AUTOSAR XML (schema 00044)
package /COM/VECTOR/CFG/WORKFLOW/SYSDESC/SYNC
  system SYSTEM: category=ECU_EXTRACT
    system mapping MAPPINGS
      data-mappings:
        data-element=COMPOSITIONTYPE.VehSpd.VehSpd, system-signal=VehSpd
        data-element=COMPOSITIONTYPE.Hr.Hr, system-signal=Hr
        data-element=COMPOSITIONTYPE.Mth.Mth, system-signal=Mth
        data-element=COMPOSITIONTYPE.ComfEna.ComfEna, system-signal=ComfEna
        data-element=COMPOSITIONTYPE.VehState.VehState, system-signal=VehState
        data-element=COMPOSITIONTYPE.Yr.Yr, system-signal=Yr
        data-element=COMPOSITIONTYPE.CGW_03_CRC.CGW_03_CRC, system-signal=CGW_03_CRC
        data-element=COMPOSITIONTYPE.WLCChrgFctEnaReq.WLCChrgFctEnaReq, system-signal=WLCChrgFctEnaReq
        data-element=COMPOSITIONTYPE.Day.Day, system-signal=Day
        data-element=COMPOSITIONTYPE.CGW_03_MsgCntr.CGW_03_MsgCntr, system-signal=CGW_03_MsgCntr
        data-element=COMPOSITIONTYPE.Sec.Sec, system-signal=Sec
        data-element=COMPOSITIONTYPE.VehOdometer.VehOdometer, system-signal=VehOdometer
        data-element=COMPOSITIONTYPE.Min.Min, system-signal=Min
        data-element=COMPOSITIONTYPE.VehState_ASIL.VehState_ASIL, system-signal=VehState_ASIL
        data-element=COMPOSITIONTYPE.ComfEna_ASIL.ComfEna_ASIL, system-signal=ComfEna_ASIL
        data-element=COMPOSITIONTYPE.ImobEnaReq.ImobEnaReq, system-signal=ImobEnaReq
        data-element=COMPOSITIONTYPE.CGW_WLC_MsgCntr.CGW_WLC_MsgCntr, system-signal=CGW_WLC_MsgCntr
        data-element=COMPOSITIONTYPE.CGW_WLC_CRC.CGW_WLC_CRC, system-signal=CGW_WLC_CRC
        data-element=COMPOSITIONTYPE.WLCImobSts.WLCImobSts, system-signal=WLCImobSts
        data-element=COMPOSITIONTYPE.UsrData0_WLC.UsrData0_WLC, system-signal=UsrData0_WLC
        data-element=COMPOSITIONTYPE.WLC_01_MsgCntr.WLC_01_MsgCntr, system-signal=WLC_01_MsgCntr
        data-element=COMPOSITIONTYPE.WLCChrgSts.WLCChrgSts, system-signal=WLCChrgSts
        data-element=COMPOSITIONTYPE.WLCCtrlSts.WLCCtrlSts, system-signal=WLCCtrlSts
        data-element=COMPOSITIONTYPE.WLC_02_MsgCntr.WLC_02_MsgCntr, system-signal=WLC_02_MsgCntr
        data-element=COMPOSITIONTYPE.UsrData4_WLC.UsrData4_WLC, system-signal=UsrData4_WLC
        data-element=COMPOSITIONTYPE.UsrData3_WLC.UsrData3_WLC, system-signal=UsrData3_WLC
        data-element=COMPOSITIONTYPE.UsrData1_WLC.UsrData1_WLC, system-signal=UsrData1_WLC
        data-element=COMPOSITIONTYPE.WLCFailSts.WLCFailSts, system-signal=WLCFailSts
        data-element=COMPOSITIONTYPE.WLC_01_CRC.WLC_01_CRC, system-signal=WLC_01_CRC
        data-element=COMPOSITIONTYPE.WLCMuteViaHW.WLCMuteViaHW, system-signal=WLCMuteViaHW
        data-element=COMPOSITIONTYPE.UsrData2_WLC.UsrData2_WLC, system-signal=UsrData2_WLC
        data-element=COMPOSITIONTYPE.UsrData5_WLC.UsrData5_WLC, system-signal=UsrData5_WLC
        data-element=COMPOSITIONTYPE.WLCChrgRate.WLCChrgRate, system-signal=WLCChrgRate
    root-software-compositions:
      root sw composition prototype COMPOSITIONTYPE: flat-map=FLATMAP, software-composition=COMPOSITIONTYPE
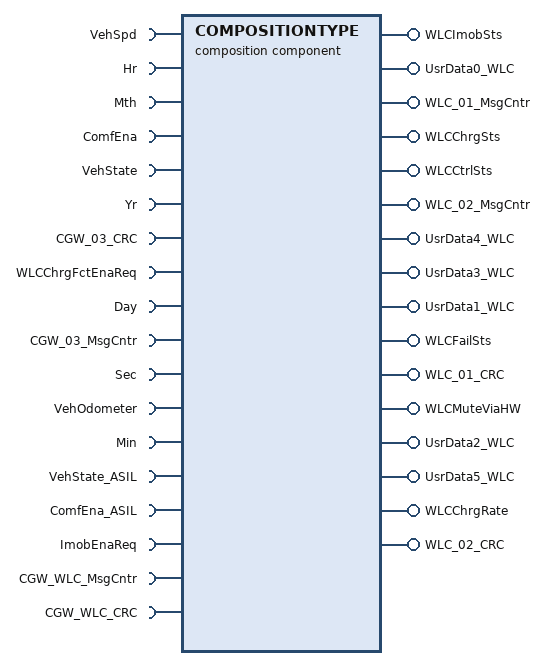
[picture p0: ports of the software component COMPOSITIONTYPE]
  composition sw component type COMPOSITIONTYPE  # UB:Derived from original system description
    18 x require port:
      VehSpd: nonqueued-receiver-com-spec{data-element=VehSpd, init-value=0}, required-interface=VehSpd
      Hr: nonqueued-receiver-com-spec{data-element=Hr, init-value=0}, required-interface=Hr
      Mth: nonqueued-receiver-com-spec{data-element=Mth, init-value=0}, required-interface=Mth
      ComfEna: nonqueued-receiver-com-spec{data-element=ComfEna, init-value=0}, required-interface=ComfEna
      VehState: nonqueued-receiver-com-spec{data-element=VehState, init-value=0}, required-interface=VehState
      Yr: nonqueued-receiver-com-spec{data-element=Yr, init-value=0}, required-interface=Yr
      CGW_03_CRC: nonqueued-receiver-com-spec{data-element=CGW_03_CRC, init-value=0}, required-interface=CGW_03_CRC
      WLCChrgFctEnaReq: nonqueued-receiver-com-spec{data-element=WLCChrgFctEnaReq, init-value=0}, required-interface=WLCChrgFctEnaReq
      Day: nonqueued-receiver-com-spec{data-element=Day, init-value=0}, required-interface=Day
      CGW_03_MsgCntr: nonqueued-receiver-com-spec{data-element=CGW_03_MsgCntr, init-value=0}, required-interface=CGW_03_MsgCntr
      Sec: nonqueued-receiver-com-spec{data-element=Sec, init-value=0}, required-interface=Sec
      VehOdometer: nonqueued-receiver-com-spec{data-element=VehOdometer, init-value=0}, required-interface=VehOdometer
      Min: nonqueued-receiver-com-spec{data-element=Min, init-value=0}, required-interface=Min
      VehState_ASIL: nonqueued-receiver-com-spec{data-element=VehState_ASIL, init-value=0}, required-interface=VehState_ASIL
      ComfEna_ASIL: nonqueued-receiver-com-spec{data-element=ComfEna_ASIL, init-value=0}, required-interface=ComfEna_ASIL
      ImobEnaReq: nonqueued-receiver-com-spec{data-element=ImobEnaReq, init-value=0}, required-interface=ImobEnaReq
      CGW_WLC_MsgCntr: nonqueued-receiver-com-spec{data-element=CGW_WLC_MsgCntr, init-value=0}, required-interface=CGW_WLC_MsgCntr
      CGW_WLC_CRC: nonqueued-receiver-com-spec{data-element=CGW_WLC_CRC, init-value=0}, required-interface=CGW_WLC_CRC
    16 x provide port:
      WLCImobSts: nonqueued-sender-com-spec{data-element=WLCImobSts, init-value=0}, provided-interface=WLCImobSts
      UsrData0_WLC: nonqueued-sender-com-spec{data-element=UsrData0_WLC, init-value=0}, provided-interface=UsrData0_WLC
      WLC_01_MsgCntr: nonqueued-sender-com-spec{data-element=WLC_01_MsgCntr, init-value=0}, provided-interface=WLC_01_MsgCntr
      WLCChrgSts: nonqueued-sender-com-spec{data-element=WLCChrgSts, init-value=0}, provided-interface=WLCChrgSts
      WLCCtrlSts: nonqueued-sender-com-spec{data-element=WLCCtrlSts, init-value=0}, provided-interface=WLCCtrlSts
      WLC_02_MsgCntr: nonqueued-sender-com-spec{data-element=WLC_02_MsgCntr, init-value=0}, provided-interface=WLC_02_MsgCntr
      UsrData4_WLC: nonqueued-sender-com-spec{data-element=UsrData4_WLC, init-value=0}, provided-interface=UsrData4_WLC
      UsrData3_WLC: nonqueued-sender-com-spec{data-element=UsrData3_WLC, init-value=0}, provided-interface=UsrData3_WLC
      UsrData1_WLC: nonqueued-sender-com-spec{data-element=UsrData1_WLC, init-value=0}, provided-interface=UsrData1_WLC
      WLCFailSts: nonqueued-sender-com-spec{data-element=WLCFailSts, init-value=0}, provided-interface=WLCFailSts
      WLC_01_CRC: nonqueued-sender-com-spec{data-element=WLC_01_CRC, init-value=0}, provided-interface=WLC_01_CRC
      WLCMuteViaHW: nonqueued-sender-com-spec{data-element=WLCMuteViaHW, init-value=0}, provided-interface=WLCMuteViaHW
      UsrData2_WLC: nonqueued-sender-com-spec{data-element=UsrData2_WLC, init-value=0}, provided-interface=UsrData2_WLC
      UsrData5_WLC: nonqueued-sender-com-spec{data-element=UsrData5_WLC, init-value=0}, provided-interface=UsrData5_WLC
      WLCChrgRate: nonqueued-sender-com-spec{data-element=WLCChrgRate, init-value=0}, provided-interface=WLCChrgRate
      WLC_02_CRC: nonqueued-sender-com-spec=WLC_02_CRC, provided-interface=WLC_02_CRC
    10 x component:
      ComM: type=ComM
      DemMaster_0: type=DemMaster_0
      DemSatellite_0: type=DemSatellite_0
      Det: type=Det
      EcuM: type=EcuM
      Os_OsCore0_swc: type=Os_OsCore0_swc
      BswM: type=BswM
      Dcm: type=Dcm
      SWC_WLCAPP: type=SWC_WLCAPP
      Communication_Read_APP: type=Communication_Read_APP
    connect BswM.Switch_ESH_ModeSwitch -> BswM.Notification_ESH_ModeNotification
    connect ComM.UR_CN_NIO_ES6_RF_CAN_SR_V3_0_e01a4c57 -> SWC_WLCAPP.UR_CN_NIO_ES6_RF_CAN_SR_V3_0_e01a4c57
    delegate Communication_Read_APP.Yr <-> outer port Yr  # UB:Derived from original system description
    delegate Communication_Read_APP.Hr <-> outer port Hr  # UB:Derived from original system description
    delegate Communication_Read_APP.Min <-> outer port Min  # UB:Derived from original system description
    delegate Communication_Read_APP.WLCChrgFctEnaReq <-> outer port WLCChrgFctEnaReq  # UB:Derived from original system description
    delegate Communication_Read_APP.ImobEnaReq <-> outer port ImobEnaReq  # UB:Derived from original system description
    delegate Communication_Read_APP.CGW_WLC_MsgCntr <-> outer port CGW_WLC_MsgCntr  # UB:Derived from original system description
    delegate Communication_Read_APP.VehOdometer <-> outer port VehOdometer  # UB:Derived from original system description
    delegate Communication_Read_APP.CGW_WLC_CRC <-> outer port CGW_WLC_CRC  # UB:Derived from original system description
    delegate Communication_Read_APP.CGW_03_MsgCntr <-> outer port CGW_03_MsgCntr  # UB:Derived from original system description
    delegate Communication_Read_APP.ComfEna_ASIL <-> outer port ComfEna_ASIL  # UB:Derived from original system description
    delegate Communication_Read_APP.VehState_ASIL <-> outer port VehState_ASIL  # UB:Derived from original system description
    delegate Communication_Read_APP.VehState <-> outer port VehState  # UB:Derived from original system description
    delegate Communication_Read_APP.CGW_03_CRC <-> outer port CGW_03_CRC  # UB:Derived from original system description
    delegate Communication_Read_APP.ComfEna <-> outer port ComfEna  # UB:Derived from original system description
    delegate Communication_Read_APP.Day <-> outer port Day  # UB:Derived from original system description
    delegate Communication_Read_APP.Mth <-> outer port Mth  # UB:Derived from original system description
    delegate Communication_Read_APP.Sec <-> outer port Sec  # UB:Derived from original system description
    delegate Communication_Read_APP.VehSpd <-> outer port VehSpd  # UB:Derived from original system description
    delegate Communication_Read_APP.WLC_02_CRC <-> outer port WLC_02_CRC  # UB:Derived from original system description
    delegate Communication_Read_APP.UsrData5_WLC <-> outer port UsrData5_WLC  # UB:Derived from original system description
    delegate Communication_Read_APP.WLCCtrlSts <-> outer port WLCCtrlSts  # UB:Derived from original system description
    delegate Communication_Read_APP.UsrData4_WLC <-> outer port UsrData4_WLC  # UB:Derived from original system description
    delegate Communication_Read_APP.UsrData0_WLC <-> outer port UsrData0_WLC  # UB:Derived from original system description
    delegate Communication_Read_APP.WLCFailSts <-> outer port WLCFailSts  # UB:Derived from original system description
    delegate Communication_Read_APP.UsrData3_WLC <-> outer port UsrData3_WLC  # UB:Derived from original system description
    delegate Communication_Read_APP.WLCMuteViaHW <-> outer port WLCMuteViaHW  # UB:Derived from original system description
    delegate Communication_Read_APP.WLC_01_CRC <-> outer port WLC_01_CRC  # UB:Derived from original system description
    delegate Communication_Read_APP.WLCImobSts <-> outer port WLCImobSts  # UB:Derived from original system description
    delegate Communication_Read_APP.WLC_02_MsgCntr <-> outer port WLC_02_MsgCntr  # UB:Derived from original system description
    delegate Communication_Read_APP.UsrData2_WLC <-> outer port UsrData2_WLC  # UB:Derived from original system description
    delegate Communication_Read_APP.WLCChrgRate <-> outer port WLCChrgRate  # UB:Derived from original system description
    delegate Communication_Read_APP.WLCChrgSts <-> outer port WLCChrgSts  # UB:Derived from original system description
    delegate Communication_Read_APP.UsrData1_WLC <-> outer port UsrData1_WLC  # UB:Derived from original system description
    delegate Communication_Read_APP.WLC_01_MsgCntr <-> outer port WLC_01_MsgCntr  # UB:Derived from original system description
    connect Dcm.DcmEcuReset -> Communication_Read_APP.DcmEcuReset
    connect Communication_Read_APP.DataServices_Diag_RWDI_LightOnOffCounter_LightOnOffCounter_Value -> Dcm.DataServices_Diag_RWDI_LightOnOffCounter_LightOnOffCounter_Value
    connect Communication_Read_APP.DataServices_Diag_VM_HardwarePartNumber -> Dcm.DataServices_Diag_VM_HardwarePartNumber
    connect Communication_Read_APP.DataServices_DcmDspData_BootloaderVersion -> Dcm.DataServices_DcmDspData_BootloaderVersion
    connect Communication_Read_APP.DataServices_DcmDspData_ConfigurarionFingerprint -> Dcm.DataServices_DcmDspData_ConfigurarionFingerprint
    connect Communication_Read_APP.DataServices_DcmDspData_ECUConfigurarion -> Dcm.DataServices_DcmDspData_ECUConfigurarion
    connect Communication_Read_APP.DataServices_DcmDspData_ECUDiagDatabaseVersion -> Dcm.DataServices_DcmDspData_ECUDiagDatabaseVersion
    connect Communication_Read_APP.DataServices_DcmDspData_ECUManufacturingDate -> Dcm.DataServices_DcmDspData_ECUManufacturingDate
    connect Communication_Read_APP.DataServices_DcmDspData_ECUProgrammingDate -> Dcm.DataServices_DcmDspData_ECUProgrammingDate
    connect Communication_Read_APP.DataServices_DcmDspData_ECUSerialNumber -> Dcm.DataServices_DcmDspData_ECUSerialNumber
    connect Communication_Read_APP.DataServices_DcmDspData_ReadActiveDiagSession -> Dcm.DataServices_DcmDspData_ReadActiveDiagSession
    connect Communication_Read_APP.DataServices_DcmDspData_ReadFingerprint -> Dcm.DataServices_DcmDspData_ReadFingerprint
    connect Communication_Read_APP.DataServices_DcmDspData_RepairShopFingerPrint -> Dcm.DataServices_DcmDspData_RepairShopFingerPrint
    connect Communication_Read_APP.DataServices_DcmDspData_SystemName -> Dcm.DataServices_DcmDspData_SystemName
    connect Communication_Read_APP.DataServices_DcmDspData_SystemSupplierIdData -> Dcm.DataServices_DcmDspData_SystemSupplierIdData
    connect Communication_Read_APP.DataServices_DcmDspData_VIN -> Dcm.DataServices_DcmDspData_VIN
    connect Communication_Read_APP.DataServices_DcmDspData_VM_CalibrarionPartNumber -> Dcm.DataServices_DcmDspData_VM_CalibrarionPartNumber
    connect Communication_Read_APP.DataServices_DcmDspData_VM_CalibrationBaseline -> Dcm.DataServices_DcmDspData_VM_CalibrationBaseline
    connect Communication_Read_APP.DataServices_DcmDspData_VM_FOTASpecialPartNumber -> Dcm.DataServices_DcmDspData_VM_FOTASpecialPartNumber
    connect Communication_Read_APP.DataServices_DcmDspData_VM_SoftwarBaseline -> Dcm.DataServices_DcmDspData_VM_SoftwarBaseline
    connect Communication_Read_APP.DataServices_DcmDspData_VM_SofwarePartNumber -> Dcm.DataServices_DcmDspData_VM_SofwarePartNumber
    connect Communication_Read_APP.DataServices_DcmDspData_VM_SparepartNumber -> Dcm.DataServices_DcmDspData_VM_SparepartNumber
    connect Communication_Read_APP.DataServices_DcmDspData_VM_Specialdatabaseline -> Dcm.DataServices_DcmDspData_VM_Specialdatabaseline
    connect Communication_Read_APP.DataServices_Diag_VM_HardwareBaseline -> Dcm.DataServices_Diag_VM_HardwareBaseline
    connect Dcm.DcmControlDtcSetting -> Communication_Read_APP.DcmControlDtcSetting
    connect Communication_Read_APP.SecurityAccess_Level_01 -> Dcm.SecurityAccess_Level_01
    connect Communication_Read_APP.SecurityAccess_Level_02 -> Dcm.SecurityAccess_Level_02
  end to end protection set E2EPROTECTIONSET
  port interface mapping set PORTINTERFACEMAPPINGSET
